VERSION ""

NS_ :

BS_:

BU_:

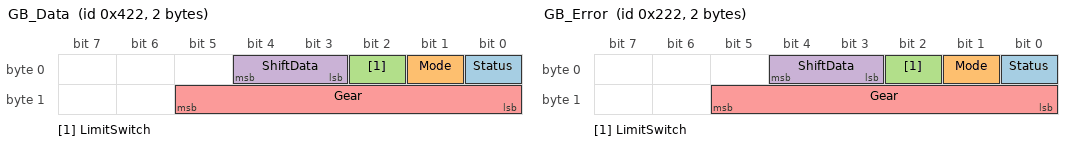
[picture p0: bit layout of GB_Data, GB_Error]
BO_ 1058 GB_Data: 2 Vector__XXX
	SG_ Status : 0|1@1+ (1,0) [0|1] "" Vector__XXX
	SG_ Mode : 1|1@1+ (1,0) [0|1] "" Vector__XXX
	SG_ LimitSwitch : 2|1@1+ (1,0) [0|1] "" Vector__XXX
	SG_ ShiftData : 3|2@1+ (1,0) [0|3] "" Vector__XXX
	SG_ Gear : 8|6@1+ (1,0) [0|15] "" Vector__XXX

BO_ 546 GB_Error: 2 Vector__XXX
	SG_ Status : 0|1@1+ (1,0) [0|1] "" Vector__XXX
	SG_ Mode : 1|1@1+ (1,0) [0|1] "" Vector__XXX
	SG_ LimitSwitch : 2|1@1+ (1,0) [0|1] "" Vector__XXX
	SG_ ShiftData : 3|2@1+ (1,0) [0|3] "" Vector__XXX
	SG_ Gear : 8|6@1+ (1,0) [0|15] "" Vector__XXX

CM_ BO_ 1058 "Gearbox Data";
CM_ SG_ 1058 Status "Status of the gearbox (working/error)";
CM_ SG_ 1058 Mode "Mode of the gearbox (gearbox/calibration)";
CM_ SG_ 1058 LimitSwitch "Status of the limit switch";
CM_ SG_ 1058 ShiftData "Encodes whether the gearbox is shifting (up/down) or not";
CM_ SG_ 1058 Gear "Current gear";
CM_ BO_ 546 "Gearbox Error";
CM_ SG_ 546 Status "Status of the gearbox (working/error)";
CM_ SG_ 546 Mode "Mode of the gearbox (gearbox/calibration)";
CM_ SG_ 546 LimitSwitch "Status of the limit switch";
CM_ SG_ 546 ShiftData "Encodes whether the gearbox is shifting (up/down) or not";
CM_ SG_ 546 Gear "Current gear";
BA_DEF_ SG_  "SPN" INT 0 524287;
BA_DEF_ BO_  "VFrameFormat" ENUM  "StandardCAN","ExtendedCAN","reserved","J1939PG";
BA_DEF_  "DatabaseVersion" STRING ;
BA_DEF_  "BusType" STRING ;
BA_DEF_  "ProtocolType" STRING ;
BA_DEF_  "DatabaseCompiler" STRING ;
BA_DEF_DEF_  "SPN" 0;
BA_DEF_DEF_  "VFrameFormat" "J1939PG";
BA_DEF_DEF_  "DatabaseVersion" "DEMO PLUS";
BA_DEF_DEF_  "BusType" "";
BA_DEF_DEF_  "ProtocolType" "";
BA_DEF_DEF_  "DatabaseCompiler" "";
BA_ "ProtocolType" "J1939";
BA_ "BusType" "CAN";
BA_ "DatabaseCompiler" "CSS ELECTRONICS (WWW.CSSELECTRONICS.COM)";
BA_ "DatabaseVersion" "1.0.0";
BA_ "SPN" SG_ 2364540158 EngineSpeed 190;
